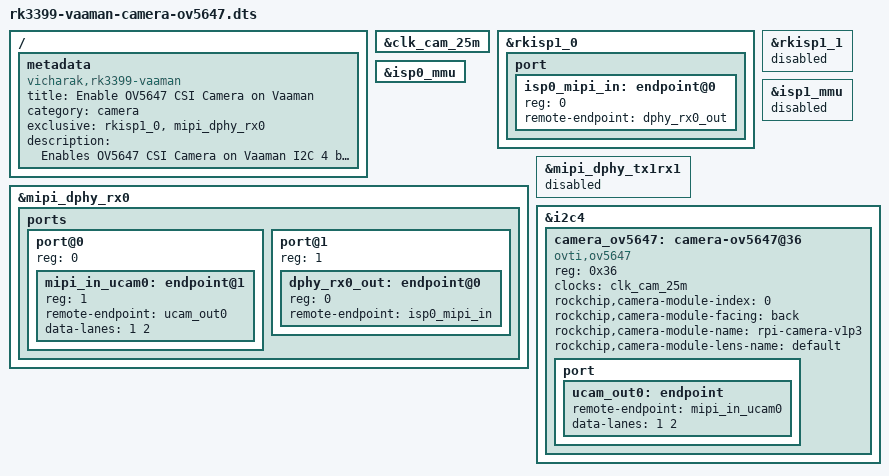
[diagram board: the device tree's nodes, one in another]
// SPDX-License-Identifier: GPL-2.0+
// Copyright (C) 2023 Vicharak Computers LLP

/dts-v1/;
/plugin/;

#include <dt-bindings/gpio/gpio.h>
#include <dt-bindings/pinctrl/rockchip.h>

/ {
	metadata {
		title = "Enable OV5647 CSI Camera on Vaaman";
		compatible = "vicharak,rk3399-vaaman", "rockchip,rk3399";
		category = "camera";
		exclusive = "rkisp1_0", "mipi_dphy_rx0";
		description = "Enables OV5647 CSI Camera on Vaaman I2C 4 bus at address 36";
	};

	fragment@0 {
		target = <&clk_cam_25m>;

		__overlay__ {
			status = "okay";
		};
	};

	fragment@1 {
		target = <&rkisp1_0>;

		__overlay__ {
			status = "okay";

			port {
				#address-cells = <1>;
				#size-cells = <0>;

				isp0_mipi_in: endpoint@0 {
					reg = <0>;
					remote-endpoint = <&dphy_rx0_out>;
				};
			};
		};
	};

	fragment@2 {
		target = <&rkisp1_1>;

		__overlay__ {
			status = "disabled";
		};
	};

	fragment@3 {
		target = <&isp0_mmu>;

		__overlay__ {
			status = "okay";
		};
	};

	fragment@4 {
		target = <&isp1_mmu>;

		__overlay__ {
			status = "disabled";
		};
	};

	fragment@5 {
		target = <&mipi_dphy_rx0>;

		__overlay__ {
			status = "okay";

			ports {
				#address-cells = <1>;
				#size-cells = <0>;

				port@0 {
					reg = <0>;
					#address-cells = <1>;
					#size-cells = <0>;

					mipi_in_ucam0: endpoint@1 {
						reg = <1>;
						remote-endpoint = <&ucam_out0>;
						data-lanes = <1 2>;
					};
				};

				port@1 {
					reg = <1>;
					#address-cells = <1>;
					#size-cells = <0>;

					dphy_rx0_out: endpoint@0 {
						reg = <0>;
						remote-endpoint = <&isp0_mipi_in>;
					};
				};
			};
		};
	};

	fragment@6 {
		target = <&mipi_dphy_tx1rx1>;

		__overlay__ {
			status = "disabled";
		};
	};

	fragment@7 {
		target = <&i2c4>;

		__overlay__ {
			status = "okay";
			#address-cells = <1>;
			#size-cells = <0>;

			camera_ov5647: camera-ov5647@36 {
				status = "okay";
				compatible = "ovti,ov5647";
				reg = <0x36>;
				clocks = <&clk_cam_25m>;
				clock-names = "xclk";
				rockchip,camera-module-index = <0>;
				rockchip,camera-module-facing = "back";
				rockchip,camera-module-name = "rpi-camera-v1p3";
				rockchip,camera-module-lens-name = "default";

				port {
					ucam_out0: endpoint {
						remote-endpoint = <&mipi_in_ucam0>;
						data-lanes = <1 2>;
					};
				};
			};
		};
	};
};
